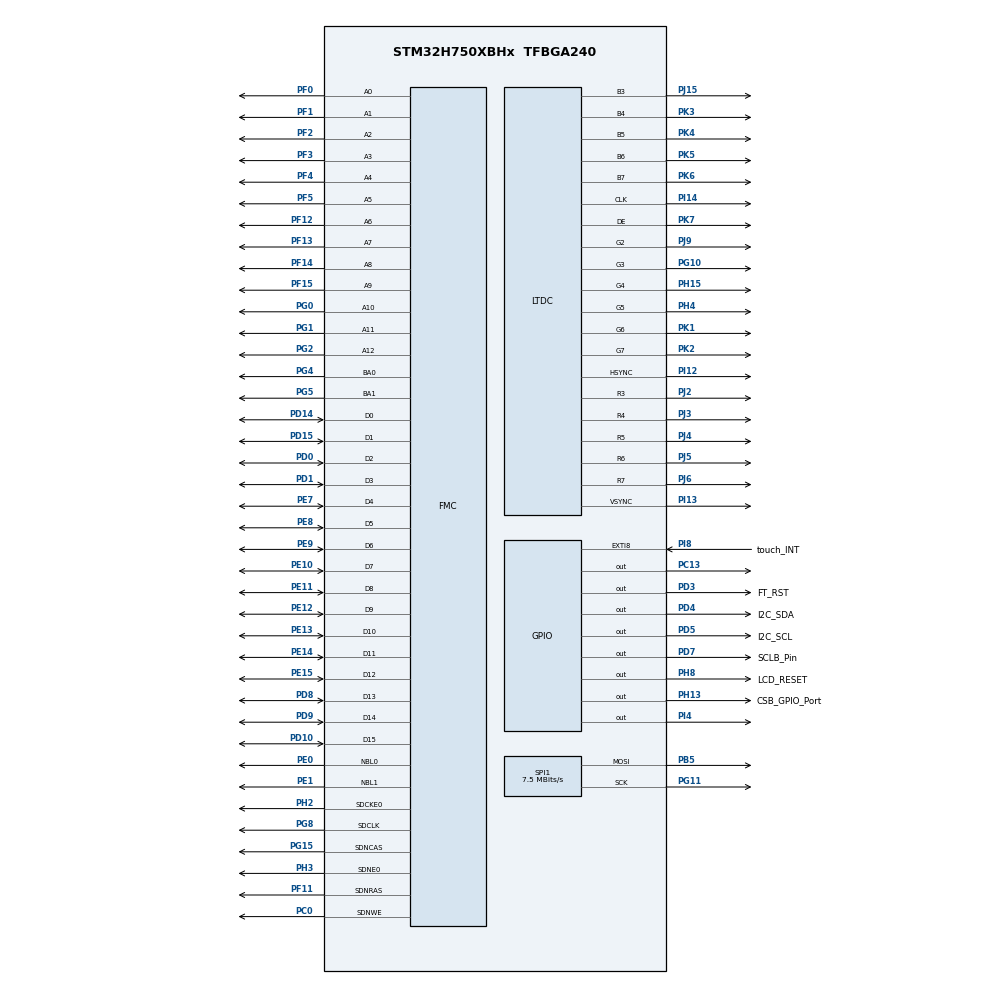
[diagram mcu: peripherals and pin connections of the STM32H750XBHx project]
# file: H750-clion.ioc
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DMA2D.ColorMode=DMA2D_OUTPUT_RGB565
DMA2D.Mode=DMA2D_M2M_PFC
FMC.CASLatency1=FMC_SDRAM_CAS_LATENCY_3
FMC.ColumnBitsNumber1=FMC_SDRAM_COLUMN_BITS_NUM_9
FMC.ExitSelfRefreshDelay1=7
FMC.LoadToActiveDelay1=2
FMC.RCDDelay1=2
FMC.RPDelay1=2
FMC.RPDelay2=2
FMC.ReadBurst1=FMC_SDRAM_RBURST_ENABLE
FMC.ReadBurst2=FMC_SDRAM_RBURST_ENABLE
FMC.ReadPipeDelay1=FMC_SDRAM_RPIPE_DELAY_1
FMC.ReadPipeDelay2=FMC_SDRAM_RPIPE_DELAY_1
FMC.RowCycleDelay1=7
FMC.RowCycleDelay2=7
FMC.SDClockPeriod1=FMC_SDRAM_CLOCK_PERIOD_2
FMC.SDClockPeriod2=FMC_SDRAM_CLOCK_PERIOD_2
FMC.SelfRefreshTime1=4
FMC.WriteRecoveryTime1=3
LTDC.ActiveH=640
LTDC.ActiveW=480
LTDC.Alpha_L0=255
LTDC.Blue=0
LTDC.DEPolarity=LTDC_DEPOLARITY_AL
LTDC.FBStartAdress_L0=0xC0000000
LTDC.Green=0
LTDC.HBP=12
LTDC.HFP=8
LTDC.HSync=2
LTDC.ImageHeight_L0=640
LTDC.ImageWidth_L0=480
LTDC.Layers=0
LTDC.PixelFormat_L0=LTDC_PIXEL_FORMAT_RGB565
LTDC.Red=100
LTDC.VBP=12
LTDC.VFP=8
LTDC.VSync=2
LTDC.WindowX1_L0=480
LTDC.WindowY1_L0=640
Mcu.Family=STM32H7
Mcu.Name=STM32H750XBHx
Mcu.Package=TFBGA240
NVIC.DMA2D_IRQn=true\:0\:0\:false\:false\:true\:true\:true\:true
NVIC.EXTI9_5_IRQn=true\:0\:0\:false\:false\:true\:true\:true\:true
NVIC.LTDC_ER_IRQn=true\:0\:0\:false\:false\:true\:true\:true\:true
NVIC.LTDC_IRQn=true\:0\:0\:false\:false\:true\:true\:true\:true
NVIC.PriorityGroup=NVIC_PRIORITYGROUP_4
NVIC.SPI1_IRQn=true\:0\:0\:false\:false\:true\:true\:true\:true
PB5.GPIO_Speed=GPIO_SPEED_FREQ_VERY_HIGH
PB5.Mode=TX_Only_Simplex_Unidirect_Master
PB5.Signal=SPI1_MOSI
PC0.Signal=FMC_SDNWE
PC13.GPIO_ModeDefaultOutputPP=GPIO_MODE_OUTPUT_PP
PC13.GPIO_PuPd=GPIO_PULLUP
PC13.PinState=GPIO_PIN_RESET
PC13.Signal=GPIO_Output
PC14-OSC32_IN\ (OSC32_IN).Mode=LSE-External-Oscillator
PC14-OSC32_IN\ (OSC32_IN).Signal=RCC_OSC32_IN
PC15-OSC32_OUT\ (OSC32_OUT).Mode=LSE-External-Oscillator
PC15-OSC32_OUT\ (OSC32_OUT).Signal=RCC_OSC32_OUT
PD0.Signal=FMC_D2_DA2
PD1.Signal=FMC_D3_DA3
PD10.Signal=FMC_D15_DA15
PD14.Signal=FMC_D0_DA0
PD15.Signal=FMC_D1_DA1
PD3.GPIO_Label=FT_RST
PD3.GPIO_PuPd=GPIO_PULLUP
PD3.GPIO_Speed=GPIO_SPEED_FREQ_VERY_HIGH
PD3.Signal=GPIO_Output
PD4.GPIO_Label=I2C_SDA
PD4.GPIO_PuPd=GPIO_PULLUP
PD4.GPIO_Speed=GPIO_SPEED_FREQ_VERY_HIGH
PD4.Signal=GPIO_Output
PD5.GPIO_Label=I2C_SCL
PD5.GPIO_ModeDefaultOutputPP=GPIO_MODE_OUTPUT_PP
PD5.GPIO_PuPd=GPIO_PULLUP
PD5.GPIO_Speed=GPIO_SPEED_FREQ_VERY_HIGH
PD5.PinState=GPIO_PIN_SET
PD5.Signal=GPIO_Output
PD7.GPIO_Label=SCLB_Pin
PD7.GPIO_ModeDefaultOutputPP=GPIO_MODE_OUTPUT_PP
PD7.GPIO_PuPd=GPIO_PULLUP
PD7.GPIO_Speed=GPIO_SPEED_FREQ_VERY_HIGH
PD7.PinState=GPIO_PIN_SET
PD7.Signal=GPIO_Output
PD8.Signal=FMC_D13_DA13
PD9.Signal=FMC_D14_DA14
PE0.Signal=FMC_NBL0
PE1.Signal=FMC_NBL1
PE10.Signal=FMC_D7_DA7
PE11.Signal=FMC_D8_DA8
PE12.Signal=FMC_D9_DA9
PE13.Signal=FMC_D10_DA10
PE14.Signal=FMC_D11_DA11
PE15.Signal=FMC_D12_DA12
PE7.Signal=FMC_D4_DA4
PE8.Signal=FMC_D5_DA5
PE9.Signal=FMC_D6_DA6
PF0.Signal=FMC_A0
PF1.Signal=FMC_A1
PF11.Signal=FMC_SDNRAS
PF12.Signal=FMC_A6
PF13.Signal=FMC_A7
PF14.Signal=FMC_A8
PF15.Signal=FMC_A9
PF2.Signal=FMC_A2
PF3.Signal=FMC_A3
PF4.Signal=FMC_A4
PF5.Signal=FMC_A5
PG0.Signal=FMC_A10
PG1.Signal=FMC_A11
PG10.GPIO_Speed=GPIO_SPEED_FREQ_VERY_HIGH
PG10.Mode=RGB565
PG10.Signal=LTDC_G3
PG11.GPIO_Speed=GPIO_SPEED_FREQ_VERY_HIGH
PG11.Mode=TX_Only_Simplex_Unidirect_Master
PG11.Signal=SPI1_SCK
PG15.Signal=FMC_SDNCAS
PG2.Signal=FMC_A12
PG4.Signal=FMC_A14_BA0
PG5.Signal=FMC_A15_BA1
PG8.Signal=FMC_SDCLK
PH0-OSC_IN\ (PH0).Mode=HSE-External-Oscillator
PH0-OSC_IN\ (PH0).Signal=RCC_OSC_IN
PH1-OSC_OUT\ (PH1).Mode=HSE-External-Oscillator
PH1-OSC_OUT\ (PH1).Signal=RCC_OSC_OUT
PH13.GPIO_Label=CSB_GPIO_Port
PH13.GPIO_ModeDefaultOutputPP=GPIO_MODE_OUTPUT_PP
PH13.GPIO_PuPd=GPIO_PULLUP
PH13.GPIO_Speed=GPIO_SPEED_FREQ_VERY_HIGH
PH13.PinState=GPIO_PIN_SET
PH13.Signal=GPIO_Output
PH15.GPIO_Speed=GPIO_SPEED_FREQ_VERY_HIGH
PH15.Mode=RGB565
PH15.Signal=LTDC_G4
PH2.Mode=SdramChipSelect1_1
PH2.Signal=FMC_SDCKE0
PH3.Mode=SdramChipSelect1_1
PH3.Signal=FMC_SDNE0
PH4.GPIO_Speed=GPIO_SPEED_FREQ_VERY_HIGH
PH4.Mode=RGB565
PH4.Signal=LTDC_G5
PH8.GPIO_Label=LCD_RESET
PH8.GPIO_ModeDefaultOutputPP=GPIO_MODE_OUTPUT_PP
PH8.GPIO_PuPd=GPIO_PULLUP
PH8.GPIO_Speed=GPIO_SPEED_FREQ_VERY_HIGH
PH8.PinState=GPIO_PIN_SET
PH8.Signal=GPIO_Output
PI12.GPIO_Speed=GPIO_SPEED_FREQ_VERY_HIGH
PI12.Mode=RGB565
PI12.Signal=LTDC_HSYNC
PI13.GPIO_Speed=GPIO_SPEED_FREQ_VERY_HIGH
PI13.Mode=RGB565
PI13.Signal=LTDC_VSYNC
PI14.GPIO_Speed=GPIO_SPEED_FREQ_VERY_HIGH
PI14.Mode=RGB565
PI14.Signal=LTDC_CLK
PI4.PinState=GPIO_PIN_SET
PI4.Signal=GPIO_Output
PI8.GPIO_Label=touch_INT
PI8.GPIO_ModeDefaultEXTI=GPIO_MODE_IT_RISING_FALLING
PI8.Signal=GPXTI8
PJ15.GPIO_Speed=GPIO_SPEED_FREQ_VERY_HIGH
PJ15.Mode=RGB565
PJ15.Signal=LTDC_B3
PJ2.GPIO_Speed=GPIO_SPEED_FREQ_VERY_HIGH
PJ2.Mode=RGB565
PJ2.Signal=LTDC_R3
PJ3.GPIO_Speed=GPIO_SPEED_FREQ_VERY_HIGH
PJ3.Mode=RGB565
PJ3.Signal=LTDC_R4
PJ4.GPIO_Speed=GPIO_SPEED_FREQ_VERY_HIGH
PJ4.Mode=RGB565
PJ4.Signal=LTDC_R5
PJ5.GPIO_Speed=GPIO_SPEED_FREQ_VERY_HIGH
PJ5.Mode=RGB565
PJ5.Signal=LTDC_R6
PJ6.GPIO_Speed=GPIO_SPEED_FREQ_VERY_HIGH
PJ6.Mode=RGB565
PJ6.Signal=LTDC_R7
PJ9.GPIO_Speed=GPIO_SPEED_FREQ_VERY_HIGH
PJ9.Mode=RGB565
PJ9.Signal=LTDC_G2
PK1.GPIO_Speed=GPIO_SPEED_FREQ_VERY_HIGH
PK1.Mode=RGB565
PK1.Signal=LTDC_G6
PK2.GPIO_Speed=GPIO_SPEED_FREQ_VERY_HIGH
PK2.Mode=RGB565
PK2.Signal=LTDC_G7
PK3.GPIO_Speed=GPIO_SPEED_FREQ_VERY_HIGH
PK3.Mode=RGB565
PK3.Signal=LTDC_B4
PK4.GPIO_Speed=GPIO_SPEED_FREQ_VERY_HIGH
PK4.Mode=RGB565
PK4.Signal=LTDC_B5
PK5.GPIO_Speed=GPIO_SPEED_FREQ_VERY_HIGH
PK5.Mode=RGB565
PK5.Signal=LTDC_B6
PK6.GPIO_Speed=GPIO_SPEED_FREQ_VERY_HIGH
PK6.Mode=RGB565
PK6.Signal=LTDC_B7
PK7.GPIO_Speed=GPIO_SPEED_FREQ_VERY_HIGH
PK7.Mode=RGB565
PK7.Signal=LTDC_DE
ProjectManager.HeapSize=0x400
ProjectManager.StackSize=0x1000
ProjectManager.TargetToolchain=STM32CubeIDE
RCC.ADCFreq_Value=120000000
RCC.APB1Freq_Value=120000000
RCC.APB2Freq_Value=120000000
RCC.APB3Freq_Value=120000000
RCC.APB4Freq_Value=120000000
RCC.CortexFreq_Value=480000000
RCC.D1PPRE=RCC_APB3_DIV2
RCC.D2PPRE1=RCC_APB1_DIV2
RCC.D2PPRE2=RCC_APB2_DIV2
RCC.D3PPRE=RCC_APB4_DIV2
RCC.DIVM1=5
RCC.DIVM2=25
RCC.DIVM3=25
RCC.DIVN1=192
RCC.DIVN2=240
RCC.DIVN3=400
RCC.DIVQ1=4
RCC.DIVR3=20
RCC.HCLKFreq_Value=240000000
RCC.HPRE=RCC_HCLK_DIV2
RCC.PLL2FRACN=0
RCC.PLL3FRACN=0
RCC.PLLFRACN=0
RCC.PLLSourceVirtual=RCC_PLLSOURCE_HSE
RCC.ProductRev=revV
RCC.SPI123CLockSelection=RCC_SPI123CLKSOURCE_PLL2
RCC.SYSCLKFreq_VALUE=480000000
RCC.SYSCLKSource=RCC_SYSCLKSOURCE_PLLCLK
RCC.USBFreq_Value=240000000
SH.FMC_A0.0=FMC_A0,13b-sda1
SH.FMC_A1.0=FMC_A1,13b-sda1
SH.FMC_A10.0=FMC_A10,13b-sda1
SH.FMC_A11.0=FMC_A11,13b-sda1
SH.FMC_A12.0=FMC_A12,13b-sda1
SH.FMC_A14_BA0.0=FMC_BA0,FourSdramBanks1
SH.FMC_A15_BA1.0=FMC_BA1,FourSdramBanks1
SH.FMC_A2.0=FMC_A2,13b-sda1
SH.FMC_A3.0=FMC_A3,13b-sda1
SH.FMC_A4.0=FMC_A4,13b-sda1
SH.FMC_A5.0=FMC_A5,13b-sda1
SH.FMC_A6.0=FMC_A6,13b-sda1
SH.FMC_A7.0=FMC_A7,13b-sda1
SH.FMC_A8.0=FMC_A8,13b-sda1
SH.FMC_A9.0=FMC_A9,13b-sda1
SH.FMC_D0_DA0.0=FMC_D0,sd-16b-d1
SH.FMC_D10_DA10.0=FMC_D10,sd-16b-d1
SH.FMC_D11_DA11.0=FMC_D11,sd-16b-d1
SH.FMC_D12_DA12.0=FMC_D12,sd-16b-d1
SH.FMC_D13_DA13.0=FMC_D13,sd-16b-d1
SH.FMC_D14_DA14.0=FMC_D14,sd-16b-d1
SH.FMC_D15_DA15.0=FMC_D15,sd-16b-d1
SH.FMC_D1_DA1.0=FMC_D1,sd-16b-d1
SH.FMC_D2_DA2.0=FMC_D2,sd-16b-d1
SH.FMC_D3_DA3.0=FMC_D3,sd-16b-d1
SH.FMC_D4_DA4.0=FMC_D4,sd-16b-d1
SH.FMC_D5_DA5.0=FMC_D5,sd-16b-d1
SH.FMC_D6_DA6.0=FMC_D6,sd-16b-d1
SH.FMC_D7_DA7.0=FMC_D7,sd-16b-d1
SH.FMC_D8_DA8.0=FMC_D8,sd-16b-d1
SH.FMC_D9_DA9.0=FMC_D9,sd-16b-d1
SH.FMC_NBL0.0=FMC_NBL0,Sd2ByteEnable1
SH.FMC_NBL1.0=FMC_NBL1,Sd2ByteEnable1
SH.FMC_SDCLK.0=FMC_SDCLK,13b-sda1
SH.FMC_SDNCAS.0=FMC_SDNCAS,13b-sda1
SH.FMC_SDNRAS.0=FMC_SDNRAS,13b-sda1
SH.FMC_SDNWE.0=FMC_SDNWE,13b-sda1
SPI1.BaudRatePrescaler=SPI_BAUDRATEPRESCALER_16
SPI1.CLKPhase=SPI_PHASE_1EDGE
SPI1.CLKPolarity=SPI_POLARITY_LOW
SPI1.CalculateBaudRate=7.5 MBits/s
SPI1.DataSize=SPI_DATASIZE_9BIT
SPI1.Direction=SPI_DIRECTION_2LINES_TXONLY
SPI1.Mode=SPI_MODE_MASTER
SPI1.VirtualType=VM_MASTER
VP_DMA2D_VS_DMA2D.Mode=DMA2D_Activate
board=custom

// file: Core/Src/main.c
/* USER CODE BEGIN Header */
/**
  ******************************************************************************
  * @file           : main.c
  * @brief          : Main program body
  ******************************************************************************
  * @attention
  *
  * Copyright (c) 2024 STMicroelectronics.
  * All rights reserved.
  *
  * This software is licensed under terms that can be found in the LICENSE file
  * in the root directory of this software component.
  * If no LICENSE file comes with this software, it is provided AS-IS.
  *
  ******************************************************************************
  */
/* USER CODE END Header */
#include "main.h"
#include "dma2d.h"
#include "ltdc.h"
#include "spi.h"
#include "gpio.h"
#include "fmc.h"

/* USER CODE BEGIN Includes */
#include "Lcd_int.h"
#include "ui.h"
#include "touch.h"
#include "lv_port_indev_template.h"
/* USER CODE END Includes */

void SystemClock_Config(void);

int main(void)
{

  /* MCU Configuration--------------------------------------------------------*/

  /* Reset of all peripherals, Initializes the Flash interface and the Systick. */
  HAL_Init();

  /* Configure the system clock */
  SystemClock_Config();

  /* Initialize all configured peripherals */
  MX_GPIO_Init();
  MX_SPI1_Init();
  MX_FMC_Init();
  MX_LTDC_Init();
  MX_DMA2D_Init();
  /* USER CODE BEGIN 2 */
    //LCD_Init();
    FT5206_Init_SoftI2C();

    lv_init();
    lv_port_disp_init();
    lv_port_indev_init();
    ui_init();
   // HAL_Delay(10);
//    HAL_Delay(10);
//    lv_obj_t *label = lv_label_create(lv_scr_act());
//    lv_label_set_text(label,"niaho");
//    lv_obj_center(label);
//
//    lv_obj_t *switch_obj = lv_switch_create(lv_scr_act());
//
//    lv_obj_set_size(switch_obj, 120, 60);
//
   // lv_obj_align(switch_obj, LV_ALIGN_CENTER, 0, 0);

  /* USER CODE END 2 */

  /* Infinite loop */
  while (1)
  {

    /* USER CODE BEGIN 3 */

      HAL_Delay(100);
          //FT5206_Scan_SoftI2C(0 );
          lv_timer_handler();

      //HAL_GPIO_TogglePin(GPIOC,GPIO_PIN_13);

  }
  /* USER CODE END 3 */
}

void SystemClock_Config(void)
{
  RCC_OscInitTypeDef RCC_OscInitStruct = {0};
  RCC_ClkInitTypeDef RCC_ClkInitStruct = {0};

  /** Supply configuration update enable
  */
  HAL_PWREx_ConfigSupply(PWR_LDO_SUPPLY);

  /** Configure the main internal regulator output voltage
  */
  __HAL_PWR_VOLTAGESCALING_CONFIG(PWR_REGULATOR_VOLTAGE_SCALE1);

  while(!__HAL_PWR_GET_FLAG(PWR_FLAG_VOSRDY)) {}

  __HAL_RCC_SYSCFG_CLK_ENABLE();
  __HAL_PWR_VOLTAGESCALING_CONFIG(PWR_REGULATOR_VOLTAGE_SCALE0);

  while(!__HAL_PWR_GET_FLAG(PWR_FLAG_VOSRDY)) {}

  /** Initializes the RCC Oscillators according to the specified parameters
  * in the RCC_OscInitTypeDef structure.
  */
  RCC_OscInitStruct.OscillatorType = RCC_OSCILLATORTYPE_HSE;
  RCC_OscInitStruct.HSEState = RCC_HSE_ON;
  RCC_OscInitStruct.PLL.PLLState = RCC_PLL_ON;
  RCC_OscInitStruct.PLL.PLLSource = RCC_PLLSOURCE_HSE;
  RCC_OscInitStruct.PLL.PLLM = 5;
  RCC_OscInitStruct.PLL.PLLN = 192;
  RCC_OscInitStruct.PLL.PLLP = 2;
  RCC_OscInitStruct.PLL.PLLQ = 4;
  RCC_OscInitStruct.PLL.PLLR = 2;
  RCC_OscInitStruct.PLL.PLLRGE = RCC_PLL1VCIRANGE_2;
  RCC_OscInitStruct.PLL.PLLVCOSEL = RCC_PLL1VCOWIDE;
  RCC_OscInitStruct.PLL.PLLFRACN = 0;
  if (HAL_RCC_OscConfig(&RCC_OscInitStruct) != HAL_OK)
  {
    Error_Handler();
  }

  /** Initializes the CPU, AHB and APB buses clocks
  */
  RCC_ClkInitStruct.ClockType = RCC_CLOCKTYPE_HCLK|RCC_CLOCKTYPE_SYSCLK
                              |RCC_CLOCKTYPE_PCLK1|RCC_CLOCKTYPE_PCLK2
                              |RCC_CLOCKTYPE_D3PCLK1|RCC_CLOCKTYPE_D1PCLK1;
  RCC_ClkInitStruct.SYSCLKSource = RCC_SYSCLKSOURCE_PLLCLK;
  RCC_ClkInitStruct.SYSCLKDivider = RCC_SYSCLK_DIV1;
  RCC_ClkInitStruct.AHBCLKDivider = RCC_HCLK_DIV2;
  RCC_ClkInitStruct.APB3CLKDivider = RCC_APB3_DIV2;
  RCC_ClkInitStruct.APB1CLKDivider = RCC_APB1_DIV2;
  RCC_ClkInitStruct.APB2CLKDivider = RCC_APB2_DIV2;
  RCC_ClkInitStruct.APB4CLKDivider = RCC_APB4_DIV2;

  if (HAL_RCC_ClockConfig(&RCC_ClkInitStruct, FLASH_LATENCY_4) != HAL_OK)
  {
    Error_Handler();
  }
}

void Error_Handler(void)
{
  __disable_irq();
  while (1)
  {
  }
}
